# STM32L010x6 register map
File version: 1.0
Registers are 32-bit, read-write, reset 0x0 unless marked. A register's access mark holds for its fields unless they carry their own. Offsets are from the block's base; [hi:lo] are bit positions; {n}, {i} and the like mark numbered series.

## SYSCFG — SysTem Configuration
Base 0x40010000
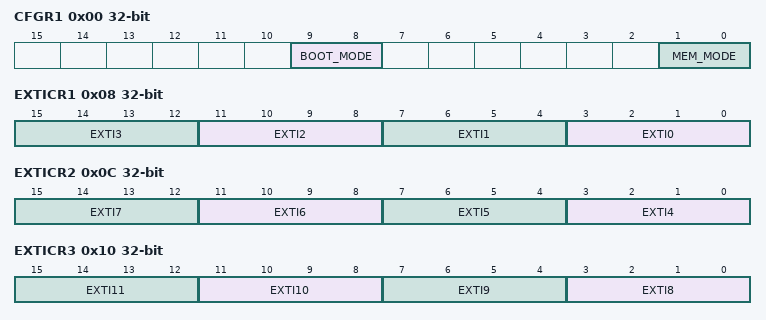
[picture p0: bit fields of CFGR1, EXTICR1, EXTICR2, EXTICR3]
0x00 CFGR1 — SYSCFG configuration register 1
  [9:8] BOOT_MODE — SYSCFG_Boot mode Config
    0=FLASH (Main Flash memory boot mode); 1=SYSTEMFLASH (System Flash memory boot mode); 3=SRAM (SRAM boot mode)
  [1:0] MEM_MODE — SYSCFG_Memory Remap Config
    0=FLASH (Main Flash memory mapped at 0x00000000); 1=SYSTEMFLASH (System Flash memory mapped at 0x00000000); 3=SRAM (SRAM mapped at 0x00000000)
0x04 CFGR2 — SYSCFG configuration register 2
  [0] FWDISEN — Firewall disable bit
0x08 EXTICR1 — SYSCFG external interrupt configuration register
  [4n+3:4n] EXTI{n} (n=0..3) — EXTI {n} configuration
0x0C EXTICR2 — SYSCFG external interrupt configuration register
  [4n-13:4n-16] EXTI{n} (n=4..7) — EXTI {n} configuration
0x10 EXTICR3 — SYSCFG external interrupt configuration register
  [4n-29:4n-32] EXTI{n} (n=8..11) — EXTI {n} configuration
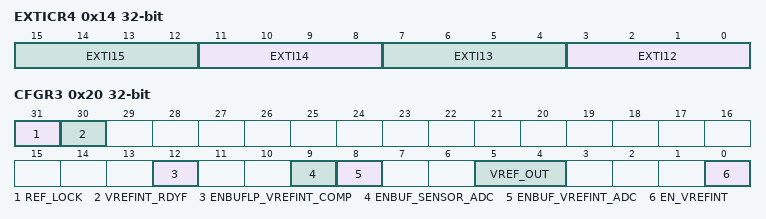
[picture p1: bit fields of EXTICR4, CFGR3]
0x14 EXTICR4 — SYSCFG external interrupt configuration register
  [4n-45:4n-48] EXTI{n} (n=12..15) — EXTI {n} configuration
0x20 CFGR3 — SYSCFG configuration register 3
  [31] REF_LOCK — CFGR3 lock bit
  [30] VREFINT_RDYF — VREFINT ready flag
  [12] ENBUFLP_VREFINT_COMP — VREFINT reference for comparator 2 enable bit
  [9] ENBUF_SENSOR_ADC — Sensor reference for ADC enable bit
  [8] ENBUF_VREFINT_ADC — VREFINT reference for ADC enable bit
  [5:4] VREF_OUT — Verf_ADC connection bit
    0=NONE (No pad connected to VREFINT_ADC); 1=IO1 (PB0 connected to VREFINT_ADC); 2=IO2 (PB1 connected to VREFINT_ADC); 3=IO1_IO2 (PB0 and PB1 connected to VREFINT_ADC)
  [0] EN_VREFINT — Vref Enable bit

## EXTI — External Interrupt/Event Controller
Base 0x40010400
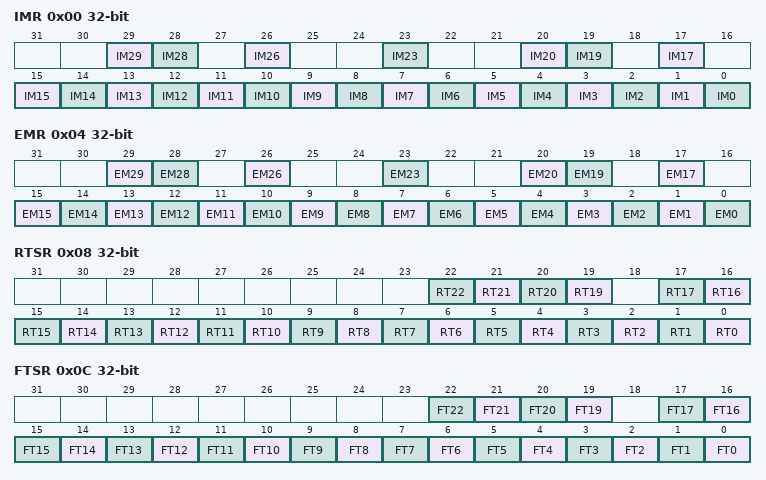
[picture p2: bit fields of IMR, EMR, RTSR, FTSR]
0x00 IMR — EXTI Interrupt mask register
  [29] IM29 — Interrupt Mask on line 29
  [28] IM28 — Interrupt Mask on line 28
  [26] IM26 — Interrupt Mask on line 26
  [23] IM23 — Interrupt Mask on line 23
  [20] IM20 — Interrupt Mask on line 20
  [19] IM19 — Interrupt Mask on line 19
  [17] IM17 — Interrupt Mask on line 17
  [n] IM{n} (n=0..15) — Interrupt Mask on line {n}
0x04 EMR — EXTI Event mask register
  [29] EM29 — Event Mask on line 29
  [28] EM28 — Event Mask on line 28
  [26] EM26 — Event Mask on line 26
  [23] EM23 — Event Mask on line 23
  [20] EM20 — Event Mask on line 20
  [19] EM19 — Event Mask on line 19
  [17] EM17 — Event Mask on line 17
  [n] EM{n} (n=0..15) — Event Mask on line {n}
0x08 RTSR — EXTI Rising trigger selection register
  [n] RT{n} (n=19..22) — Rising trigger event configuration bit of line {n}
  [n] RT{n} (n=0..17) — Rising trigger event configuration bit of line {n}
0x0C FTSR — EXTI Falling trigger selection register
  [n] FT{n} (n=19..22) — Falling trigger event configuration bit of line {n}
  [n] FT{n} (n=0..17) — Falling trigger event configuration bit of line {n}
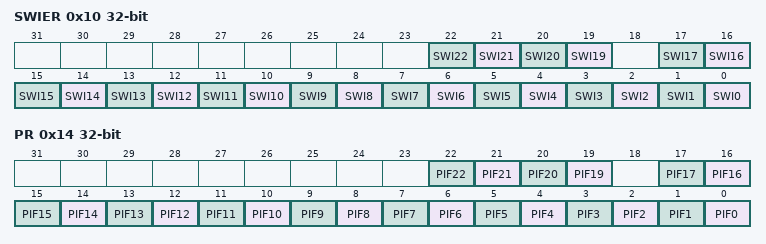
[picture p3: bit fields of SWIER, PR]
0x10 SWIER — EXTI Software interrupt event register
  [n] SWI{n} (n=19..22) — Software Interrupt on line {n}
  [n] SWI{n} (n=0..17) — Software Interrupt on line {n}
0x14 PR — EXTI Pending register
  [n] PIF{n} (n=19..22) — Pending bit {n}
  [n] PIF{n} (n=0..17) — Pending bit {n}

## SPI1 — Serial Peripheral Interface
Base 0x40013000
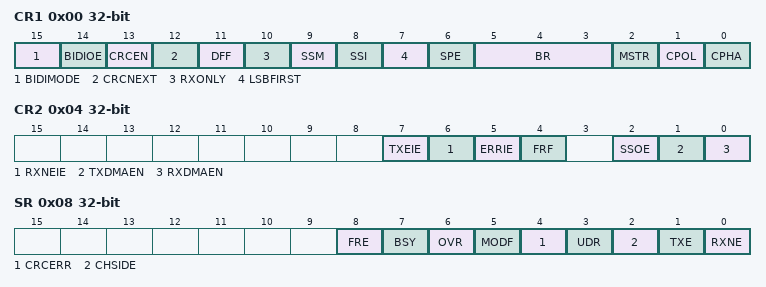
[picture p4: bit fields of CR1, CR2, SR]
0x00 CR1 — SPI Control register 1
  [15] BIDIMODE — Bidirectional data mode enable
  [14] BIDIOE — Output enable in bidirectional mode
  [13] CRCEN — Hardware CRC calculation enable
  [12] CRCNEXT — Transmit CRC next
  [11] DFF — Data Frame Format
    0=DATAWIDTH_8BIT (Data length for SPI transfer: 8 bits); 1=DATAWIDTH_16BIT (Data length for SPI transfer: 16 bits)
  [10] RXONLY — Receive only
  [9] SSM — Software slave management
  [8] SSI — Internal slave select
  [7] LSBFIRST — Frame Format
    1=LSB_FIRST (Data is transmitted/received with the LSB first); 0=MSB_FIRST (Data is transmitted/received with the MSB first)
  [6] SPE — SPI Enable
  [5:3] BR — BR[2:0] bits (Baud Rate Control)
    0=DIV2 (BaudRate control equal to fPCLK/2); 1=DIV4 (BaudRate control equal to fPCLK/4); 2=DIV8 (BaudRate control equal to fPCLK/8); 3=DIV16 (BaudRate control equal to fPCLK/16); 4=DIV32 (BaudRate control equal to fPCLK/32); 5=DIV64 (BaudRate control equal to fPCLK/64); 6=DIV128 (BaudRate control equal to fPCLK/128); 7=DIV256 (BaudRate control equal to fPCLK/256)
  [2] MSTR — Master Selection
  [1] CPOL — Clock Polarity
    0=LOW (Clock to 0 when idle); 1=HIGH (Clock to 1 when idle)
  [0] CPHA — Clock Phase
    0=PHASE_1EDGE (First clock transition is the first data capture edge); 1=PHASE_2EDGE (Second clock transition is the first data capture edge)
0x04 CR2 — SPI Control register 2
  [7] TXEIE — Tx buffer Empty Interrupt Enable
  [6] RXNEIE — RX buffer Not Empty Interrupt Enable
  [5] ERRIE — Error Interrupt Enable
  [4] FRF — Frame Format Enable
    0=MOTOROLA (Motorola mode. Used as default value); 1=TI (TI mode)
  [2] SSOE — SS Output Enable
  [1] TXDMAEN — Tx Buffer DMA Enable
  [0] RXDMAEN — Rx Buffer DMA Enable
0x08 SR — SPI Status register
  [8] FRE — TI frame format error
  [7] BSY — Busy flag
  [6] OVR — Overrun flag
  [5] MODF — Mode fault
  [4] CRCERR — CRC Error flag
  [3] UDR — Underrun flag
  [2] CHSIDE — Channel side
  [1] TXE — Transmit buffer Empty
  [0] RXNE — Receive buffer Not Empty
0x0C DR — SPI data register
  [15:0] DR — Data Register
0x10 CRCPR — SPI CRC polynomial register
  [15:0] CRCPOLY — CRC polynomial register
0x14 RXCRCR — SPI Rx CRC register
  [15:0] RXCRC
0x18 TXCRCR — SPI Tx CRC register
  [15:0] TXCRC
